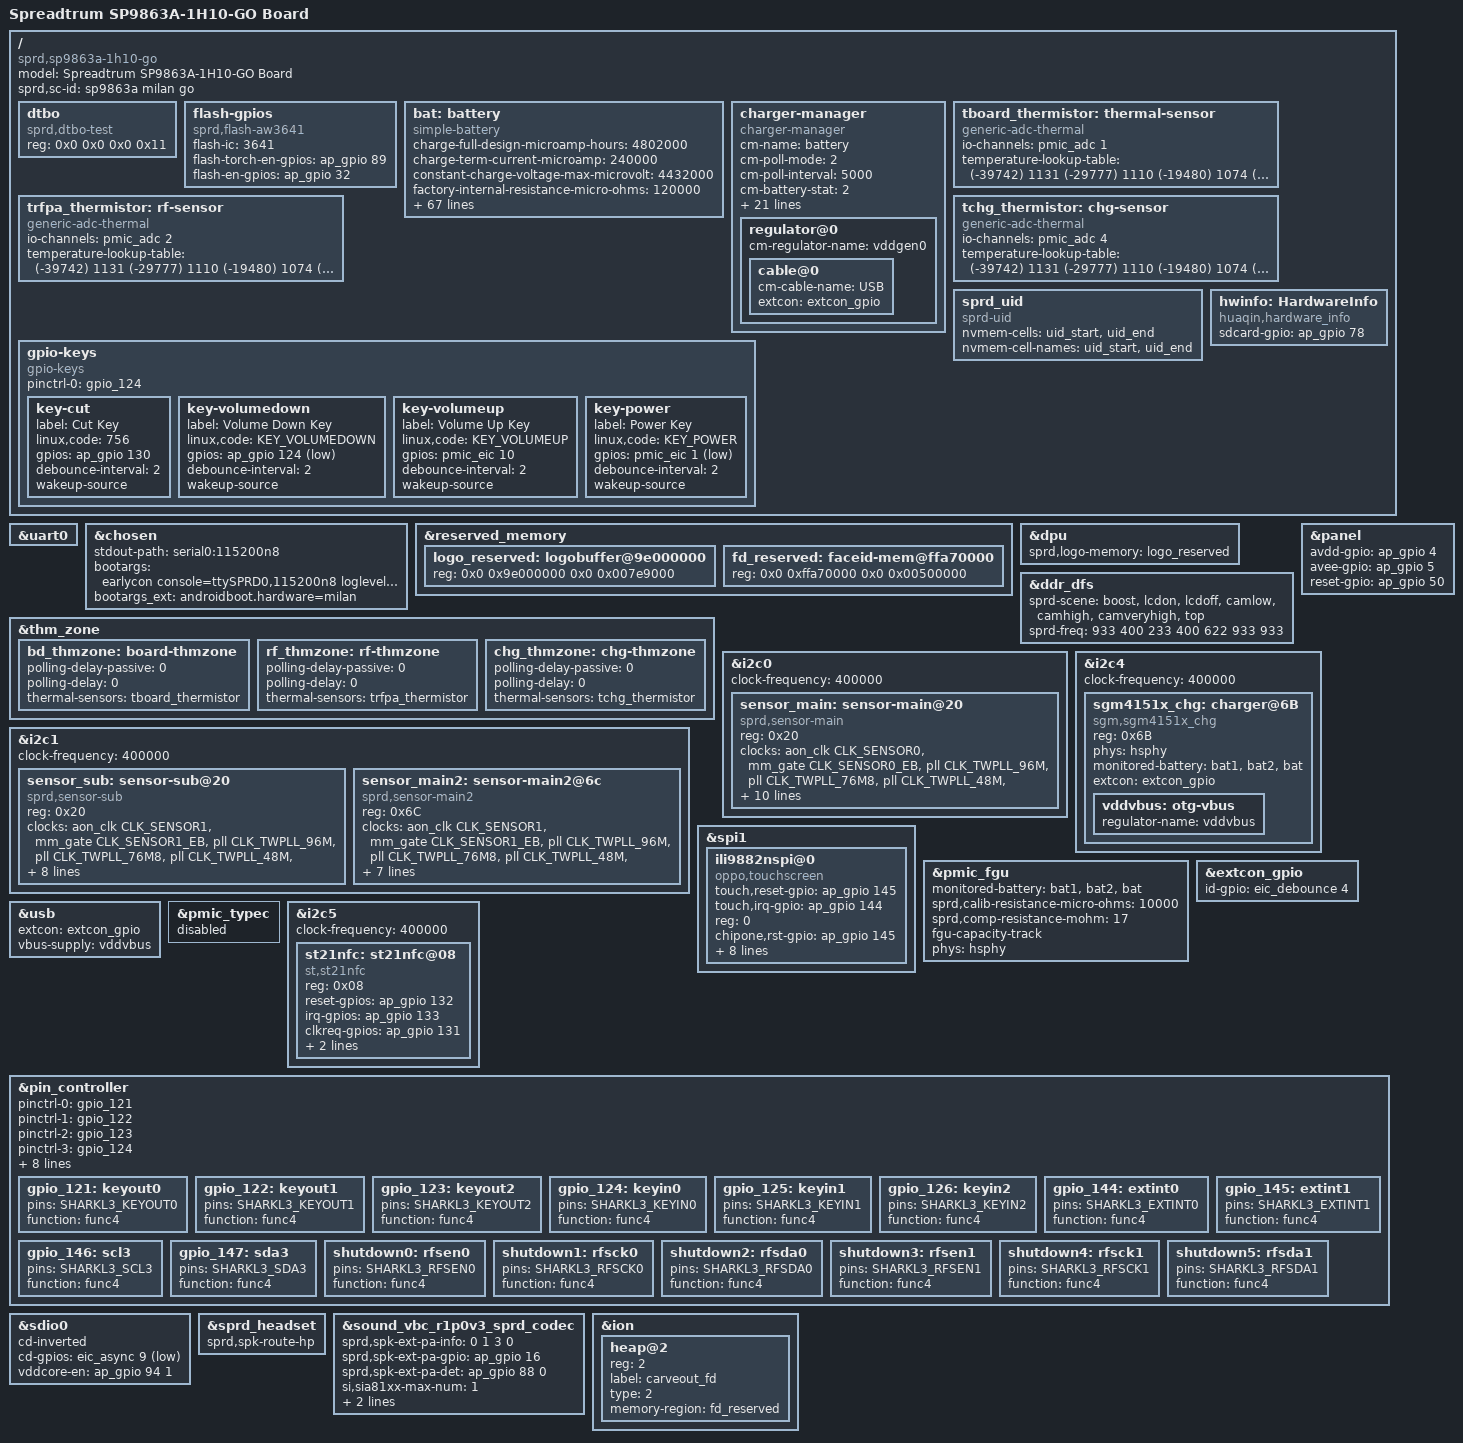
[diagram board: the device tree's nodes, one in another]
/dts-v1/;
/plugin/;
#include <dt-bindings/input/input.h>
#include <dt-bindings/gpio/gpio.h>
#include <dt-bindings/clock/sprd,sc9863a-clk.h>
#include "lcd/lcd_dummy_mipi.dtsi"
//#include "lcd/lcd_icnl9911_milan_hdplus_txd.dtsi"
#include "lcd/lcd_ft8006s_milan_hdplus_boe.dtsi"
#include "lcd/lcd_icnl9911_milan_hdplus_lxk.dtsi"
#include "./Spard-sia8100x.dtsi"
#include "battery/milan_batt_1.dtsi"
#include "battery/milan_batt_2.dtsi"

/ {
	model = "Spreadtrum SP9863A-1H10-GO Board";

	compatible = "sprd,sp9863a-1h10-go", "sprd,sc9863a";

	sprd,sc-id = "sp9863a milan go";

	fragment {
		target-path = "/";
		__overlay__ {
			#address-cells = <2>;
			#size-cells = <2>;
			dtbo: dtbo {
				compatible = "sprd,dtbo-test";
				reg = <0x0 0x0 0x0 0x11>;
			};

			/*** pwm_backlight: sprd_backlight {
				compatible = "pwm-backlight";
				pwms = <&pwms 1 30000>;
				pwm-names = "backlight";
				brightness-levels = <
								  2   2   2   2
					  2   2   2   3   4   5   6   7   8   9
					 10  11  12  13  14  15  16  17  18  19
					 20  21  22  23  24  25  26  27  28  29
					 30  31  32  33  34  35  36  37  38  39
					 40  41  42  43  44  45  46  47  48  49
					 50  51  52  53  54  55  56  57  58  59
					 60  61  62  63  64  65  66  67  68  69
					 70  71  72  73  74  75  76  77  78  79
					 80  81  82  83  84  85  86  87  88  89
					 90  91  92  93  94  95  96  97  98  99
					100 101 102 103 104 105 106 107 108 109
					110 111 112 113 114 115 116 117 118 119
					120 121 122 123 124 125 126 127 128 129
					130 131 132 133 134 135 136 137 138 139
					140 141 142 143 144 145 146 147 148 149
					150 151 152 153 154 155 156 157 158 159
					160 161 162 163 164 165 166 167 168 169
					170 171 172 173 174 175 176 177 178 179
					180 181 182 183 184 185 186 187 188 189
					190 191 192 193 194 195 196 197 198 199
					200 201 202 203 204 205 206 207 208 209
					210 211 212 213 214 215 216 217 218 219
					220 221 222 223 224 225 226 227 228 229
					230 231 232 233 234 235 236 237 238 239
					240 241 242 243 244 245 246 247 248 249
					250 251
				>;
				default-brightness-level = <33>;
			}; ***/

			flash-gpios {
				compatible = "sprd,flash-aw3641";
 				flash-ic = <3641>;
 				flash-torch-en-gpios = <&ap_gpio 89 0>;
 				flash-en-gpios = <&ap_gpio 32 0>;
 			};
			
			bat: battery {
				compatible = "simple-battery";
				charge-full-design-microamp-hours = <4802000>;
				charge-term-current-microamp = <240000>;
				constant-charge-voltage-max-microvolt = <4432000>;
				factory-internal-resistance-micro-ohms = <120000>;
				voltage-min-design-microvolt = <3455000>;
				fullbatt-voltage = <4370000>;
				fullbatt-current = <240000>;
				fullbatt-track-end-vol = <4370000>;
				fullbatt-track-end-cur = <260000>;
				first-calib-voltage = <3570000>;
				first-calib-capacity = <40>;

				ocv-capacity-celsius = <20>;
				ocv-capacity-table-0 = <4382000 100>, <4324000 95>, <4266000 90>,
							<4208000 85>, <4151000 80>, <4097000 75>,
							<4048000 70>, <4002000 65>, <3957000 60>,
							<3902000 55>, <3866000 50>, <3841000 45>,
							<3821000 40>, <3804000 35>, <3790000 30>,
							<3770000 25>, <3750000 20>, <3726000 15>,
							<3698000 10>, <3684000 5>, <3400000 0>;
				voltage-temp-table = <1404000 650>, <1307000 700>, <1203000 750>,
							<1095000 800>, <986000 850>, <878000 900>,
							<775000 950>, <678000 1000>, <590000 1050>,
							<510000 1100>, <440000 1150>, <378000 1200>,
							<324000 1250>, <278000 1300>, <238000 1350>,
							<204000 1400>, <175000 1450>, <150000 1500>,
							<129000 1550>, <111000 1600>, <96000 1650>,
							<83000 1700>, <73000 1750>, <63000 1800>,
							<55000 1850>, <48000 1900>, <42000 1950>;
				capacity-temp-table = <45 100>, <25 100>, <10 98>, <0 89>, <(-10) 79>;
				resistance-temp-table = <45 83>, <25 100>, <10 178>, <0 880>, <(-10) 1012>;

				charge-sdp-current-microamp = <570000 500000>;
				charge-dcp-current-microamp = <2300000 2000000>;
				charge-cdp-current-microamp = <1520000 1500000>;
				charge-unknown-current-microamp = <2300000 2100000>;

				dcp-jeita-temp-table = <900 920 0 4432000 0 4180000>,
					<1000 1020  950000  4432000 720000 4180000>,
					<1050 1070 2300000 4432000 1200000 4180000>,
					<1120 1140 2300000 4432000 1200000 4180000>,
					<1160 1180 2300000 4432000 2300000 4432000>,
					<1450 1430 2300000 4432000 2300000 4432000>,
					<1530 1510 1200000 4128000 1200000 4128000>;
				sdp-jeita-temp-table = <900 920 0 4432000 0 4180000>,
					<1000 1020  570000 4432000 570000 4180000>,
					<1050 1070 570000 4432000 570000 4432000>,
					<1120 1140 570000 4432000 570000 4432000>,
					<1160 1180 570000 4432000 570000 4432000>,
					<1450 1430 570000 4432000 570000 4432000>,
					<1530 1510 570000 4128000 570000 4128000>;
				cdp-jeita-temp-table = <900 920 0 4432000 0 4180000>,
					<1000 1020  950000  4432000 720000 4180000>,
					<1050 1070 1520000 4432000 1200000 4180000>,
					<1120 1140 1520000 4432000 1520000 4432000>,
					<1160 1180 1520000 4432000 1520000 4432000>,
					<1450 1430 1520000 4432000 1520000 4432000>,
					<1530 1510 1200000 4128000 1200000 4128000>;
				unknown-jeita-temp-table = <900 920 0 4432000 0 4180000>,
					<1000 1020  950000  4432000 720000 4180000>,
					<1050 1070 2300000 4432000 1200000 4180000>,
					<1120 1140 2300000 4432000 1200000 4180000>,
					<1160 1180 2300000 4432000 2300000 4432000>,
					<1450 1430 2300000 4432000 2300000 4432000>,
					<1530 1510 1200000 4128000 1200000 4128000>;
				force-jeita-status = <2>;
			};

			charger-manager {
				status = "okay";
				compatible = "charger-manager";
				cm-name = "battery";
				cm-poll-mode = <2>;
				cm-poll-interval = <5000>;
				cm-battery-stat = <2>;

				cm-fullbatt-vchkdrop-ms = <30000>;
				cm-fullbatt-vchkdrop-volt = <100000>;
				cm-fullbatt-capacity = <100>;

				cm-num-chargers = <1>;
				cm-chargers = "sgm4151x_charger";
				cm-fuel-gauge = "sc27xx-fgu";

				/* in deci centigrade */
				cm-battery-cold = <200>;
				cm-battery-cold-in-minus;
				cm-battery-hot = <800>;
				cm-battery-temp-diff = <100>;

				/* Allow charging for 25.6hr */
				cm-charging-max = <92160000>;
				/* recovery charging after stop charging 45min */
				cm-discharging-max = <2700000>;

				/* the interval to feed charger watchdog */
				cm-wdt-interval = <60>;

				/* drop voltage in microVolts to allow shutdown */
				cm-shutdown-voltage = <3400000>;

				/* when 99% of the time is exceeded, it will be forced to 100% */
				cm-tickle-time-out = <580>;

				/* how much time to allow capacity change */
				cm-one-cap-time = <30>;

				/* when the safe charging voltage is exceeded, stop charging */
				cm-charge-voltage-max = <5800000>;
				/* drop voltage in microVolts to restart charging */
				cm-charge-voltage-drop = <350000>;

				monitored-battery = <&bat1 &bat2 &bat>;

				cm-thermal-zone = "board-thmzone";

			//	cm-cap-remap-table = <1 2 3>, <2 3 2>, <98 99 2>, <99 100 3>;

				io-channels = <&pmic_adc 3>;
				io-channel-names = "bat-id-vol";
				regulator@0 {
					cm-regulator-name = "vddgen0";
					cable@0 {
						cm-cable-name = "USB";
						extcon = <&extcon_gpio>;
					};
				};
			};

			tboard_thermistor:thermal-sensor {
				compatible = "generic-adc-thermal";
				#thermal-sensor-cells = <0>;
				io-channels = <&pmic_adc 1>;
				io-channel-names = "sensor-channel";
				temperature-lookup-table = < (-39742) 1131
							(-29777) 1110
							(-19480) 1074
							(-4679) 983
							10110 838
							24805 654
							44922 413
							54903 316
							64895 238
							74884 178
							84883 133
							94883 100
							104880 75
							114889 57
							124872 43 >;
			};

			trfpa_thermistor:rf-sensor {
				compatible = "generic-adc-thermal";
				#thermal-sensor-cells = <0>;
				io-channels = <&pmic_adc 2>;
				io-channel-names = "sensor-channel";
				temperature-lookup-table = < (-39742) 1131
							(-29777) 1110
							(-19480) 1074
							(-4679) 983
							10110 838
							24805 654
							44922 413
							54903 316
							64895 238
							74884 178
							84883 133
							94883 100
							104880 75
							114889 57
							124872 43 >;
			};
			
			tchg_thermistor:chg-sensor {
				compatible = "generic-adc-thermal";
				#thermal-sensor-cells = <0>;
				io-channels = <&pmic_adc 4>;
				io-channel-names = "sensor-channel";
				temperature-lookup-table = < (-39742) 1131
							(-29777) 1110
							(-19480) 1074
							(-4679) 983
							10110 838
							24805 654
							44922 413
							54903 316
							64895 238
							74884 178
							84883 133
							94883 100
							104880 75
							114889 57
							124872 43 >;
			};
			gpio-keys {
				compatible = "gpio-keys";
				pinctrl-names = "gpio_124";
				pinctrl-0 = <&gpio_124>;
				key-cut {
					label = "Cut Key";
					linux,code = <756>;
					gpios = <&ap_gpio 130 GPIO_ACTIVE_HIGH>;
					debounce-interval = <2>;
					wakeup-source;
				};
				key-volumedown {
					label = "Volume Down Key";
					linux,code = <KEY_VOLUMEDOWN>;
					gpios = <&ap_gpio 124 GPIO_ACTIVE_LOW>;
					debounce-interval = <2>;
					wakeup-source;
				};
				key-volumeup {
					label = "Volume Up Key";
					linux,code = <KEY_VOLUMEUP>;
					gpios = <&pmic_eic 10 GPIO_ACTIVE_HIGH>;
					debounce-interval = <2>;
					wakeup-source;
				};
				key-power {
					label = "Power Key";
					linux,code =<KEY_POWER>;
					gpios = <&pmic_eic 1 GPIO_ACTIVE_LOW>;
					debounce-interval = <2>;
					wakeup-source;
				};
			};
			sprd_uid {
				compatible = "sprd-uid";
				nvmem-cells = <&uid_start>, <&uid_end>;
				nvmem-cell-names = "uid_start", "uid_end";
			};
			/*Used to show hardware information for hq factory mode*/
 			hwinfo:HardwareInfo {
 				compatible = "huaqin,hardware_info";
 				sdcard-gpio = <&ap_gpio 78 0>;
 				status = "okay";
 			};
		};
	};
};

&uart0 {

 status = "okay";
 

};
	
&chosen {
	
	stdout-path = "serial0:115200n8";
	bootargs = "earlycon console=ttySPRD0,115200n8 loglevel=1 init=/init root=/dev/ram0 rw printk.devkmsg=on androidboot.boot_devices=soc/soc:ap-ahb/20600000.sdio dummy_hcd.num=0 swiotlb=1 initcall_debug=1";

	bootargs_ext = "androidboot.hardware=milan";
};

&reserved_memory {
	#address-cells = <2>;
	#size-cells = <2>;

	logo_reserved: logobuffer@9e000000 {
		reg = <0x0 0x9e000000 0x0 0x007e9000>;
	};

	fd_reserved: faceid-mem@ffa70000{
		reg = <0x0 0xffa70000 0x0 0x00500000>;
	};
};

&dpu {
	sprd,logo-memory = <&logo_reserved>;
};


&ddr_dfs {
	sprd-scene = "boost", "lcdon", "lcdoff", "camlow",
		"camhigh", "camveryhigh", "top";
	sprd-freq = <933 400 233 400 622 933 933>;
};

&panel {
	/*** sprd,backlight = <&pwm_backlight>; ***/
	avdd-gpio = <&ap_gpio 4 GPIO_ACTIVE_HIGH>;
	avee-gpio = <&ap_gpio 5 GPIO_ACTIVE_HIGH>;
	reset-gpio = <&ap_gpio 50 GPIO_ACTIVE_HIGH>;
};

&thm_zone {
	bd_thmzone: board-thmzone {
		polling-delay-passive = <0>;
		polling-delay = <0>;
		thermal-sensors = <&tboard_thermistor>;
	};
	rf_thmzone: rf-thmzone {
		polling-delay-passive = <0>;
		polling-delay = <0>;
		thermal-sensors = <&trfpa_thermistor>;
	};
	chg_thmzone: chg-thmzone {
		polling-delay-passive = <0>;
		polling-delay = <0>;
		thermal-sensors = <&tchg_thermistor>;
	};
};

&i2c0 {
	#address-cells = <1>;
	#size-cells = <0>;

	status = "okay";
	clock-frequency = <400000>;

	sensor_main: sensor-main@20 {
		compatible = "sprd,sensor-main";
		reg = <0x20>;
		clock-names = "clk_src","sensor_eb",
			"clk_96m","clk_76m8",
			"clk_48m","clk_26m";
		clocks = <&aon_clk CLK_SENSOR0>, <&mm_gate CLK_SENSOR0_EB>,
			<&pll CLK_TWPLL_96M>,<&pll CLK_TWPLL_76M8>,
			<&pll CLK_TWPLL_48M>,<&ext_26m>;
		vddio-supply = <&vddcamio>;
		vddcama-supply = <&vddcama>;
		vddcamd-supply = <&vddcamd>;
		vddcammot-supply = <&vddcammot>;
		sprd,phyid = <1>;
		csi = <&csi0>;
		reset-gpios = <&ap_gpio 44 0>;
		power-down-gpios = <&ap_gpio 46 0>;
		power-domains = <&mm_domain>;
	};
};

&i2c1 {
	#address-cells = <1>;
	#size-cells = <0>;

	status = "okay";
	clock-frequency = <400000>;

	sensor_sub: sensor-sub@20 {
		compatible = "sprd,sensor-sub";
		reg = <0x20>;
		clock-names = "clk_src","sensor_eb",
			"clk_96m","clk_76m8",
			"clk_48m","clk_26m";
		clocks = <&aon_clk CLK_SENSOR1>, <&mm_gate CLK_SENSOR1_EB>,
			<&pll CLK_TWPLL_96M>,<&pll CLK_TWPLL_76M8>,
			<&pll CLK_TWPLL_48M>,<&ext_26m>;
		vddio-supply = <&vddcamio>;
		vddcama-supply = <&vddcama>;
		vddcamd-supply = <&vddcamd>;
		vddcammot-supply = <&vddcammot>;
		sprd,phyid = <2>;
		csi = <&csi1>;
		reset-gpios = <&ap_gpio 41 0>;
		/*power-down-gpios = <&ap_gpio 40 0>;
		power-domains = <&mm_domain>;*/
	};

	sensor_main2: sensor-main2@6c {
		compatible = "sprd,sensor-main2";
		reg = <0x6C>;
		clock-names = "clk_src","sensor_eb",
			"clk_96m","clk_76m8",
			"clk_48m","clk_26m";
		clocks = <&aon_clk CLK_SENSOR1>, <&mm_gate CLK_SENSOR1_EB>,
			<&pll CLK_TWPLL_96M>,<&pll CLK_TWPLL_76M8>,
			<&pll CLK_TWPLL_48M>,<&ext_26m>;
		vddio-supply = <&vddcamio>;
		vddcama-supply = <&vddcama>;
		sprd,phyid = <3>;
		csi = <&csi1>;
		/*reset-gpios = <&ap_gpio 45 0>;*/
		power-down-gpios = <&ap_gpio 47 0>;
		power-domains = <&mm_domain>;
	};
};

&i2c4 {
	#address-cells = <1>;
	#size-cells = <0>;

	status = "okay";
	clock-frequency = <400000>;
/*
	sgm41513_chg: charger@1A {
		compatible = "sgm,sgm41513_chg";
		reg = <0x1A>;
		phys = <&hsphy>;
		monitored-battery = <&bat1 &bat2 &bat>;
		extcon = <&extcon_gpio>;
		vddvbus:otg-vbus {
			regulator-name = "vddvbus";
		};
	};
*/	
	sgm4151x_chg: charger@6B {
		compatible = "sgm,sgm4151x_chg";
		reg = <0x6B>;
		phys = <&hsphy>;
		monitored-battery = <&bat1 &bat2 &bat>;
		extcon = <&extcon_gpio>;
		
		vddvbus:otg-vbus {
			regulator-name = "vddvbus";
		};
	};
};
&spi1 {
	#address-cells = <1>;
	#size-cells = <0>;
	status = "okay";
	ili9882nspi@0{
	compatible = "oppo,touchscreen";
	touch,reset-gpio = <&ap_gpio 145 0>;
	touch,irq-gpio = <&ap_gpio 144 0>;
	reg = <0>;
	chipone,rst-gpio = <&ap_gpio 145 0>;
	chipone,irq-gpio = <&ap_gpio 144 0>;
	chipone,x-res = <720>;
	chipone,y-res = <1600>;
	reg_chip_select = <0>;
	
	touch,rst-gpio = <&ap_gpio 145 0>;
	/***touch,irq-gpio = <&ap_gpio 144 0>;***/
	focaltech,max-touch-number = <10>;
	focaltech,display-coords =  <0 0 720 1600>;
	
	spi-max-frequency = <10000000>;
	};
};
&pmic_fgu {
	monitored-battery = <&bat1 &bat2 &bat>;
	sprd,calib-resistance-micro-ohms = <10000>;
	sprd,comp-resistance-mohm = <17>;

	fgu-capacity-track;
	phys = <&hsphy>;
};

&extcon_gpio {
	id-gpio = <&eic_debounce 4 GPIO_ACTIVE_HIGH>;
};

&usb{
	extcon = <&extcon_gpio>;
	status = "okay";
	vbus-supply = <&vddvbus>;
/*	vbus1-supply = <&vddvbus1>;*/
};

&pmic_typec {
	status = "disabled";
};

&i2c5 {
	#address-cells = <1>;
	#size-cells = <0>;
        status = "ok";
	clock-frequency = <400000>;
        st21nfc: st21nfc@08 {
                compatible = "st,st21nfc";
                reg = <0x08>;
                reset-gpios = <&ap_gpio 132 0>;
                irq-gpios = <&ap_gpio 133 0>;
                clkreq-gpios = <&ap_gpio 131 0>;
                status = "ok";
		clock-names = "nfc_ref_clk","source","enable";
		clocks = <&aon_clk CLK_AUX0>, <&ext_26m>, <&aonapb_gate CLK_AUX0_EB>;
        };
};


&pin_controller {
	pinctrl-names =
	/* keyout0 ~ keyout2 */
	"gpio_121", "gpio_122", "gpio_123",
	/* keyin0 ~ keyin2 */
	"gpio_124", "gpio_125", "gpio_126",
	/* extint0, extint1, scl3, sda3 */
	"gpio_144", "gpio_145", "gpio_146", "gpio_147",
	/* Note:If create a new board,need to add the shutdown node */
	"shutdown";
	pinctrl-0 = <&gpio_121>;
	pinctrl-1 = <&gpio_122>;
	pinctrl-2 = <&gpio_123>;
	pinctrl-3 = <&gpio_124>;
	pinctrl-4 = <&gpio_125>;
	pinctrl-5 = <&gpio_126>;
	pinctrl-6 = <&gpio_144>;
	pinctrl-7 = <&gpio_145>;
	pinctrl-8 = <&gpio_146>;
	pinctrl-9 = <&gpio_147>;
	pinctrl-10 = <&shutdown0
			&shutdown1
			&shutdown2
			&shutdown3
			&shutdown4
			&shutdown5>;

	gpio_121: keyout0 {
		pins = "SHARKL3_KEYOUT0";
		function = "func4";
	};

	gpio_122: keyout1 {
		pins = "SHARKL3_KEYOUT1";
		function = "func4";
	};

	gpio_123: keyout2 {
		pins = "SHARKL3_KEYOUT2";
		function = "func4";
	};

	gpio_124: keyin0 {
		pins = "SHARKL3_KEYIN0";
		function = "func4";
	};

	gpio_125: keyin1 {
		pins = "SHARKL3_KEYIN1";
		function = "func4";
	};

	gpio_126: keyin2 {
		pins = "SHARKL3_KEYIN2";
		function = "func4";
	};

	gpio_144: extint0 {
		pins = "SHARKL3_EXTINT0";
		function = "func4";
	};

	gpio_145: extint1 {
		pins = "SHARKL3_EXTINT1";
		function = "func4";
	};

	gpio_146: scl3 {
		pins = "SHARKL3_SCL3";
		function = "func4";
	};

	gpio_147: sda3 {
		pins = "SHARKL3_SDA3";
		function = "func4";
	};

	shutdown0: rfsen0 {
		pins = "SHARKL3_RFSEN0";
		function = "func4";
	};

	shutdown1: rfsck0 {
		pins = "SHARKL3_RFSCK0";
		function = "func4";
	};

	shutdown2: rfsda0 {
		pins = "SHARKL3_RFSDA0";
		function = "func4";
	};

	shutdown3: rfsen1 {
		pins = "SHARKL3_RFSEN1";
		function = "func4";
	};

	shutdown4: rfsck1 {
		pins = "SHARKL3_RFSCK1";
		function = "func4";
	};

	shutdown5: rfsda1 {
		pins = "SHARKL3_RFSDA1";
		function = "func4";
	};
};

&sdio0 {
	status = "okay";
	cd-inverted;
	cd-gpios = <&eic_async 9 1>;
	vddcore-en = <&ap_gpio 94 1>;
};

&sprd_headset {
	status = "okay";
	sprd,spk-route-hp;

};

&sound_vbc_r1p0v3_sprd_codec {
	status = "okay";
	/*ext_control_type, hook selection, mode, gpio share*/
	sprd,spk-ext-pa-info = <0 1 3 0>;
	sprd,spk-ext-pa-gpio = <&ap_gpio 16 0>;
	sprd,spk-ext-pa-det = <&ap_gpio 88 0>;

	si,sia81xx-max-num = <1>;
	si,sia81xx-aux-devs = <&sia81xx_L>;
	si,sia81xx-aux-devs-prefix = "SpkrLeft";
};

&ion {
	#address-cells = <1>;
	#size-cells = <0>;

	heap@2 {
		reg = <2>;
		label = "carveout_fd";
		type = <2>;
		memory-region = <&fd_reserved>;
	};
};
